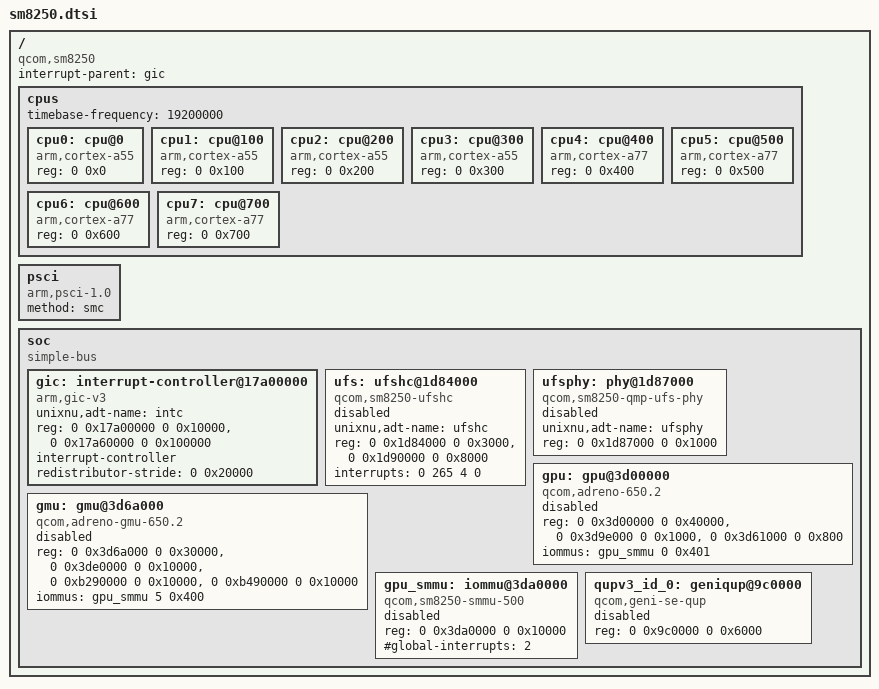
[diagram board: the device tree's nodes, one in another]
// SPDX-License-Identifier: BSD-3-Clause
// Qualcomm SM8250 / SM8250-AC (kona) shared hardware description.
//
// Addresses are SM8250 platform facts. The device repository verifies each one
// against the board's own device tree (/proc/device-tree under Android, or the FDT
// the bootloader passes) before a driver consumes it. Board memory, reserved
// regions and peripheral policy belong in the board DTS.

/ {
    compatible = "qcom,sm8250";
    #address-cells = <2>;
    #size-cells = <2>;
    interrupt-parent = <&gic>;

    cpus {
        #address-cells = <2>;
        #size-cells = <0>;
        // Qualcomm SM8xxx architectural counter.
        timebase-frequency = <19200000>;

        // Kryo 585 Silver, Cortex-A55.
        cpu0: cpu@0 { device_type = "cpu"; compatible = "arm,cortex-a55"; reg = <0 0x0>; };
        cpu1: cpu@100 { device_type = "cpu"; compatible = "arm,cortex-a55"; reg = <0 0x100>; };
        cpu2: cpu@200 { device_type = "cpu"; compatible = "arm,cortex-a55"; reg = <0 0x200>; };
        cpu3: cpu@300 { device_type = "cpu"; compatible = "arm,cortex-a55"; reg = <0 0x300>; };

        // Kryo 585 Gold (A77) and Gold Prime (A77).
        cpu4: cpu@400 { device_type = "cpu"; compatible = "arm,cortex-a77"; reg = <0 0x400>; };
        cpu5: cpu@500 { device_type = "cpu"; compatible = "arm,cortex-a77"; reg = <0 0x500>; };
        cpu6: cpu@600 { device_type = "cpu"; compatible = "arm,cortex-a77"; reg = <0 0x600>; };
        cpu7: cpu@700 { device_type = "cpu"; compatible = "arm,cortex-a77"; reg = <0 0x700>; };
    };

    psci { compatible = "arm,psci-1.0"; method = "smc"; };

    soc {
        compatible = "simple-bus";
        #address-cells = <2>;
        #size-cells = <2>;
        ranges;

        // GICv3: one 64 KiB distributor frame and eight 128 KiB redistributor
        // frames, one per CPU.
        gic: interrupt-controller@17a00000 {
            compatible = "arm,gic-v3";
            unixnu,adt-name = "intc";
            reg = <0 0x17a00000 0 0x10000>, <0 0x17a60000 0 0x100000>;
            #interrupt-cells = <4>;
            #address-cells = <0>;
            interrupt-controller;
            redistributor-stride = <0 0x20000>;
        };

        // UFS 3.0 host controller and its QMP PHY. The board enables them when a
        // reviewed storage component for kona is selected.
        ufs: ufshc@1d84000 {
            compatible = "qcom,sm8250-ufshc", "qcom,ufshc";
            unixnu,adt-name = "ufshc";
            // Host register block and inline crypto engine, and the host interrupt,
            // verified against a kona board's live device tree (SPI 0x109 = 265).
            reg = <0 0x1d84000 0 0x3000>, <0 0x1d90000 0 0x8000>;
            reg-names = "ufs_mem", "ufs_ice";
            interrupts = <0 265 4 0>;
            status = "disabled";
        };

        ufsphy: phy@1d87000 {
            compatible = "qcom,sm8250-qmp-ufs-phy";
            unixnu,adt-name = "ufsphy";
            reg = <0 0x1d87000 0 0x1000>;
            status = "disabled";
        };

        // Adreno 650, its GMU and the GPU SMMU. No catalog component has A650 scope
        // yet, so the board leaves them disabled.
        gpu: gpu@3d00000 {
            compatible = "qcom,adreno-650.2", "qcom,adreno";
            reg = <0 0x3d00000 0 0x40000>, <0 0x3d9e000 0 0x1000>, <0 0x3d61000 0 0x800>;
            reg-names = "kgsl_3d0_reg_memory", "cx_mem", "cx_dbgc";
            iommus = <&gpu_smmu 0 0x401>;
            status = "disabled";
        };

        gmu: gmu@3d6a000 {
            compatible = "qcom,adreno-gmu-650.2", "qcom,adreno-gmu";
            reg = <0 0x3d6a000 0 0x30000>, <0 0x3de0000 0 0x10000>,
                  <0 0xb290000 0 0x10000>, <0 0xb490000 0 0x10000>;
            reg-names = "gmu", "rscc", "gmu_pdc", "gmu_pdc_seq";
            iommus = <&gpu_smmu 5 0x400>;
            status = "disabled";
        };

        gpu_smmu: iommu@3da0000 {
            compatible = "qcom,sm8250-smmu-500", "qcom,adreno-smmu", "arm,mmu-500";
            reg = <0 0x3da0000 0 0x10000>;
            #iommu-cells = <2>;
            #global-interrupts = <2>;
            status = "disabled";
        };

        // QUPv3 wrapper 0. Serial engines, including the one a touch controller may
        // sit on, live here; the board selects the engine it uses.
        qupv3_id_0: geniqup@9c0000 {
            compatible = "qcom,geni-se-qup";
            reg = <0 0x9c0000 0 0x6000>;
            #address-cells = <2>;
            #size-cells = <2>;
            ranges;
            status = "disabled";
        };
    };
};
